# M2354 register map
File version: 1.0
Registers are 32-bit, read-write, reset 0x0 unless marked. A register's access mark holds for its fields unless they carry their own. Offsets are from the block's base; [hi:lo] are bit positions; {n}, {i} and the like mark numbered series.

## SYS (part 1 of 2) — SYS Register Map
Base 0x40000000
0x00 SYS_PDID ro reset 0x235400 — Part Device Identification Number Register
  [31:0] PDID — Part Device Identification Number (Read Only). This register reflects device part number code. Software can read this register to identify which device is used.
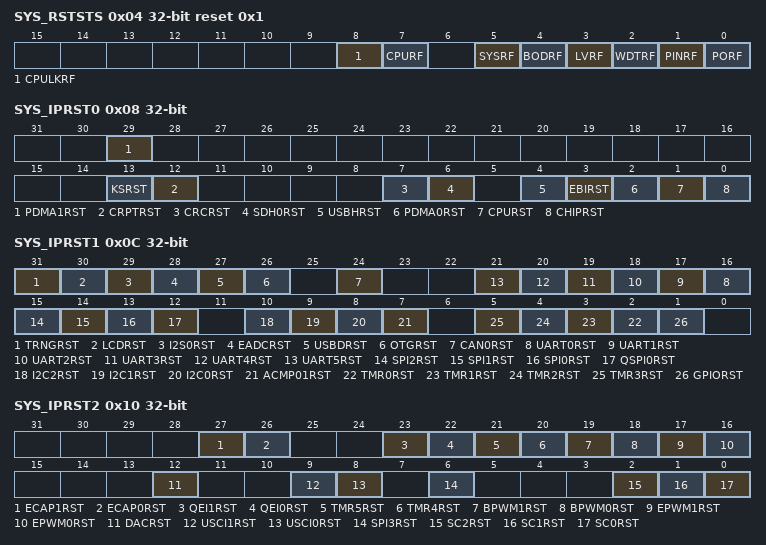
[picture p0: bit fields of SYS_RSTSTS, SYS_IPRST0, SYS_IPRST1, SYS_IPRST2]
0x04 SYS_RSTSTS reset 0x1 — System Reset Status Register
  [8] CPULKRF — CPU Lockup Reset Flag. The CPU Lockup reset flag is set by hardware if Cortex-M23 lockup happened. Note 1: Write 1 to clear this bit to 0. Note 2: When CPU lockup happened under ICE is connected, this flag will set to 1 but chip will not reset.
    0=No reset from CPU lockup happened; 1=The Cortex-M23 lockup happened and chip is reset
  [7] CPURF — CPU Reset Flag. The CPU reset flag is set by hardware if software writes CPURST (SYS_IPRST0[1]) 1 to reset the Cortex-M23 core and Flash Memory Controller (FMC). Note: Write 1 to clear this bit to 0.
    0=No reset from CPU; 1=The Cortex-M23 core and FMC are reset by software setting CPURST to 1
  [5] SYSRF — System Reset Flag. The system reset flag is set by the 'Reset Signal' from the Cortex-M23 core to indicate the previous reset source. Note: Write 1 to clear this bit to 0.
    0=No reset from the Cortex-M23; 1=The Cortex-M23 had issued the reset signal to reset the system by writing 1 to the bit SYSRESETREQ(AIRCR[2], Application Interrupt and Reset Control Register, address = 0xE000ED0C) in system control registers of Cortex-M23 core
  [4] BODRF — BOD Reset Flag. The BOD reset flag is set by the 'Reset Signal' from the Brown-out Detector to indicate the previous reset source. Note: Write 1 to clear this bit to 0.
    0=No reset from BOD; 1=The BOD had issued the reset signal to reset the system
  [3] LVRF — LVR Reset Flag. The LVR reset flag is set by the 'Reset Signal' from the Low Voltage Reset Controller to indicate the previous reset source. Note: Write 1 to clear this bit to 0.
    0=No reset from LVR; 1=The LVR controller had issued the reset signal to reset the system
  [2] WDTRF — WDT Reset Flag. The WDT reset flag is set by the 'Reset Signal' from the Watchdog Timer or Window Watchdog Timer to indicate the previous reset source. Note 1: Write 1 to clear this bit to 0. Note 2: Watchdog Timer register RSTF(WDT_CTL[2]) bit is set if the system has been reset by WDT time-out reset. Window Watchdog Timer register WWDTRF(WWDT_STATUS[1]) bit is set if the system has been reset by WWDT time-out reset. Note 3: Extra Watchdog Timer register RSTF(EWDT_CTL[2]) bit is set if the system has been reset by EWDT time-out reset. Extra Window Watchdog Timer register WWDTRF(EWWDT_STATUS[1]) bit is set if the system has been reset by EWWDT time-out reset.
    0=No reset from watchdog timer or window watchdog timer; 1=The watchdog timer or window watchdog timer had issued the reset signal to reset the system
  [1] PINRF — nRESET Pin Reset Flag. The nRESET pin reset flag is set by the 'Reset Signal' from the nRESET Pin to indicate the previous reset source. Note: Write 1 to clear this bit to 0.
    0=No reset from nRESET pin; 1=Pin nRESET had issued the reset signal to reset the system
  [0] PORF — POR Reset Flag. The POR reset flag is set by the 'Reset Signal' from the Power-on Reset (POR) Controller or bit CHIPRST (SYS_IPRST0[0]) to indicate the previous reset source. Note: Write 1 to clear this bit to 0.
    0=No reset from POR or CHIPRST; 1=Power-on Reset (POR) or CHIPRST had issued the reset signal to reset the system
0x08 SYS_IPRST0 — Peripheral Reset Control Register 0
  [29] PDMA1RST — PDMA1 Controller Reset (Write Protect). Setting this bit to 1 will generate a reset signal to the PDMA1. User needs to set this bit to 0 to release from reset state. Note: This bit is write protected. Refer to the SYS_REGLCTL register.
    0=PDMA1 controller normal operation; 1=PDMA1 controller reset
  [13] KSRST — Key Store Controller Reset (Write Protect). Setting this bit to 1 will generate a reset signal to the Key Store controller. User needs to set this bit to 0 to release from the reset state. Note: This bit is write protected. Refer to the SYS_REGLCTL register.
    0=Key Store controller normal operation; 1=Key Store controller reset
  [12] CRPTRST — CRYPTO Controller Reset (Write Protect). Setting this bit to 1 will generate a reset signal to the CRYPTO controller. User needs to set this bit to 0 to release from the reset state. Note: This bit is write protected. Refer to the SYS_REGLCTL register.
    0=CRYPTO controller normal operation; 1=CRYPTO controller reset
  [7] CRCRST — CRC Calculation Controller Reset (Write Protect). Set this bit to 1 will generate a reset signal to the CRC calculation controller. User needs to set this bit to 0 to release from the reset state. Note: This bit is write protected. Refer to the SYS_REGLCTL register.
    0=CRC calculation controller normal operation; 1=CRC calculation controller reset
  [6] SDH0RST — SDHOST0 Controller Reset (Write Protect). Setting this bit to 1 will generate a reset signal to the SDHOST0 controller. User needs to set this bit to 0 to release from the reset state. Note: This bit is write protected. Refer to the SYS_REGLCTL register.
    0=SDHOST0 controller normal operation; 1=SDHOST0 controller reset
  [4] USBHRST — USB Host Controller Reset (Write Protect). Set this bit to 1 will generate a reset signal to the USB Host. User needs to set this bit to 0 to release from the reset state. Note: This bit is write protected. Refer to the SYS_REGLCTL register.
    0=USB Host controller normal operation; 1=USB Host controller reset
  [3] EBIRST — EBI Controller Reset (Write Protect). Set this bit to 1 will generate a reset signal to the EBI. User needs to set this bit to 0 to release from the reset state. Note: This bit is write protected. Refer to the SYS_REGLCTL register.
    0=EBI controller normal operation; 1=EBI controller reset
  [2] PDMA0RST — PDMA0 Controller Reset (Write Protect). Setting this bit to 1 will generate a reset signal to the PDMA0 (always secure). User needs to set this bit to 0 to release from reset state. Note: This bit is write protected. Refer to the SYS_REGLCTL register.
    0=PDMA0 controller normal operation; 1=PDMA0 controller reset
  [1] CPURST — Processor Core One-shot Reset (Write Protect). Setting this bit will only reset the processor core and Flash Memory Controller(FMC), and this bit will automatically return to 0 after the 2 clock cycles. Note: This bit is write protected. Refer to the SYS_REGLCTL register.
    0=Processor core normal operation; 1=Processor core one-shot reset
  [0] CHIPRST — Chip One-shot Reset (Write Protect). Setting this bit will reset the whole chip, including Processor core and all peripherals, and this bit will automatically return to 0 after the 2 clock cycles. The CHIPRST is same as the POR reset, all the chip controllers is reset and the chip setting from Flash are also reload. About the difference between CHIPRST and SYSRESETREQ(AIRCR[2]), please refer to section 6.2.2. Note: This bit is write protected. Refer to the SYS_REGLCTL register.
    0=Chip normal operation; 1=Chip one-shot reset
0x0C SYS_IPRST1 — Peripheral Reset Control Register 1
  [31] TRNGRST — TRNG Controller Reset
    0=TRNG controller normal operation; 1=TRNG controller reset
  [30] LCDRST — LCD Controller Reset
    0=LCD controller normal operation; 1=LCD controller reset
  [29] I2S0RST — I2S0 Controller Reset
    0=I2S0 controller normal operation; 1=I2S0 controller reset
  [28] EADCRST — EADC Controller Reset
    0=EADC controller normal operation; 1=EADC controller reset
  [27] USBDRST — USBD Controller Reset
    0=USBD controller normal operation; 1=USBD controller reset
  [26] OTGRST — OTG Controller Reset
    0=OTG controller normal operation; 1=OTG controller reset
  [24] CAN0RST — CAN0 Controller Reset
    0=CAN0 controller normal operation; 1=CAN0 controller reset
  [n+16] UART{n}RST (n=0..5) — UART{n} Controller Reset
    0=UART{n} controller normal operation; 1=UART{n} controller reset
  [15] SPI2RST — SPI2 Controller Reset
    0=SPI2 controller normal operation; 1=SPI2 controller reset
  [14] SPI1RST — SPI1 Controller Reset
    0=SPI1 controller normal operation; 1=SPI1 controller reset
  [13] SPI0RST — SPI0 Controller Reset
    0=SPI0 controller normal operation; 1=SPI0 controller reset
  [12] QSPI0RST — QSPI0 Controller Reset
    0=QSPI0 controller normal operation; 1=QSPI0 controller reset
  [10] I2C2RST — I2C2 Controller Reset
    0=I2C2 controller normal operation; 1=I2C2 controller reset
  [9] I2C1RST — I2C1 Controller Reset
    0=I2C1 controller normal operation; 1=I2C1 controller reset
  [8] I2C0RST — I2C0 Controller Reset
    0=I2C0 controller normal operation; 1=I2C0 controller reset
  [7] ACMP01RST — Analog Comparator 0/1 Controller Reset
    0=Analog Comparator 0/1 controller normal operation; 1=Analog Comparator 0/1 controller reset
  [n+2] TMR{n}RST (n=0..3) — Timer{n} Controller Reset
    0=Timer{n} controller normal operation; 1=Timer{n} controller reset
  [1] GPIORST — GPIO Controller Reset
    0=GPIO controller normal operation; 1=GPIO controller reset
0x10 SYS_IPRST2 — Peripheral Reset Control Register 2
  [27] ECAP1RST — ECAP1 Controller Reset
    0=ECAP1 controller normal operation; 1=ECAP1 controller reset
  [26] ECAP0RST — ECAP0 Controller Reset
    0=ECAP0 controller normal operation; 1=ECAP0 controller reset
  [23] QEI1RST — QEI1 Controller Reset
    0=QEI1 controller normal operation; 1=QEI1 controller reset
  [22] QEI0RST — QEI0 Controller Reset
    0=QEI0 controller normal operation; 1=QEI0 controller reset
  [21] TMR5RST — Timer5 Controller Reset
    0=Timer5 controller normal operation; 1=Timer5 controller reset
  [20] TMR4RST — Timer4 Controller Reset
    0=Timer4 controller normal operation; 1=Timer4 controller reset
  [19] BPWM1RST — BPWM1 Controller Reset
    0=BPWM1 controller normal operation; 1=BPWM1 controller reset
  [18] BPWM0RST — BPWM0 Controller Reset
    0=BPWM0 controller normal operation; 1=BPWM0 controller reset
  [17] EPWM1RST — EPWM1 Controller Reset
    0=EPWM1 controller normal operation; 1=EPWM1 controller reset
  [16] EPWM0RST — EPWM0 Controller Reset
    0=EPWM0 controller normal operation; 1=EPWM0 controller reset
  [12] DACRST — DAC Controller Reset
    0=DAC controller normal operation; 1=DAC controller reset
  [9] USCI1RST — USCI1 Controller Reset
    0=USCI1 controller normal operation; 1=USCI1 controller reset
  [8] USCI0RST — USCI0 Controller Reset
    0=USCI0 controller normal operation; 1=USCI0 controller reset
  [6] SPI3RST — SPI3 Controller Reset
    0=SPI3 controller normal operation; 1=SPI3 controller reset
  [2] SC2RST — SC2 Controller Reset
    0=SC2 controller normal operation; 1=SC2 controller reset
  [1] SC1RST — SC1 Controller Reset
    0=SC1 controller normal operation; 1=SC1 controller reset
  [0] SC0RST — SC0 Controller Reset
    0=SC0 controller normal operation; 1=SC0 controller reset
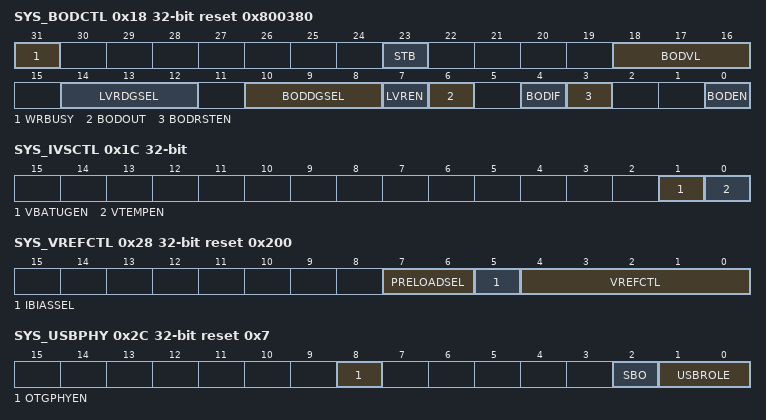
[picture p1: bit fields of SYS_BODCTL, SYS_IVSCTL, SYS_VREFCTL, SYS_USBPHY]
0x18 SYS_BODCTL reset 0x800380 (reset mask 0xFFF0FFF0) — Brown-out Detector Control Register
  [31] WRBUSY ro — Write Busy Flag (Read Only). If SYS_BODCTL is written, this bit is asserted automatically by hardware, and is de-asserted when write procedure is finished.
    0=SYS_BODCTL register is ready for write operation; 1=SYS_BODCTL register is busy on the last write operation. Other write operations are ignored
  [23] STB ro — Circuit Stable Flag (Read Only). This bit indicates LVR and BOD already stable, system cannot detect LVR and BOD event when this bit is not set.
  [18:16] BODVL — Brown-out Detector Threshold Voltage Selection (Write Protect). The default value is set by Flash controller user configuration register CBOV (CONFIG0 [23:21]). Note: These bits are write protected. Refer to the SYS_REGLCTL register.
    0=Brown-out Detector threshold voltage is 1.6V; 1=Brown-out Detector threshold voltage is 1.8V; 2=Brown-out Detector threshold voltage is 2.0V; 3=Brown-out Detector threshold voltage is 2.2V; 4=Brown-out Detector threshold voltage is 2.4V; 5=Brown-out Detector threshold voltage is 2.6V; 6=Brown-out Detector threshold voltage is 2.8V; 7=Brown-out Detector threshold voltage is 3.0V
  [14:12] LVRDGSEL — LVR Output De-glitch Time Select (Write Protect). Note: These bits are write protected. Refer to the SYS_REGLCTL register.
    0=Without de-glitch function; 1=4 system clock (HCLK); 2=8 system clock (HCLK); 3=16 system clock (HCLK); 4=32 system clock (HCLK); 5=64 system clock (HCLK); 6=128 system clock (HCLK); 7=256 system clock (HCLK)
  [10:8] BODDGSEL — Brown-out Detector Output De-glitch Time Select (Write Protect). Note: These bits are write protected. Refer to the SYS_REGLCTL register.
    0=BOD output is sampled by LIRC clock; 1=4 system clock (HCLK); 2=8 system clock (HCLK); 3=16 system clock (HCLK); 4=32 system clock (HCLK); 5=64 system clock (HCLK); 6=128 system clock (HCLK); 7=256 system clock (HCLK)
  [7] LVREN — Low Voltage Reset Enable Bit (Write Protect). The LVR function resets the chip when the input power voltage is lower than LVR circuit setting. LVR function is enabled by default. Note 1: After enabling the bit, the LVR function will be active with 200us delay for LVR output stable (default). Note 2: This bit is write protected. Refer to the SYS_REGLCTL register.
    0=Low Voltage Reset function Disabled; 1=Low Voltage Reset function Enabled
  [6] BODOUT ro — Brown-out Detector Output Status (Read Only). It means the detected voltage is lower than BODVL setting. If the BODEN is 0, BOD function disabled, this bit always responds 0.
    0=Brown-out Detector output status is 0; 1=Brown-out Detector output status is 1
  [4] BODIF — Brown-out Detector Interrupt Flag. Note: Write 1 to clear this bit to 0.
    0=Brown-out Detector does not detect any voltage draft at VDD down through or up through the voltage of BODVL setting; 1=When Brown-out Detector detects the VDD is dropped down through the voltage of BODVL setting or the VDD is raised up through the voltage of BODVL setting, this bit is set to 1 and the brown-out interrupt is requested if brown-out interrupt is enabled
  [3] BODRSTEN — Brown-out Reset Enable Bit (Write Protect). The default value is set by Flash controller user configuration register CBORST(CONFIG0[20]) bit. Note 1: When the Brown-out Detector function is enabled (BODEN high) and BOD reset function is enabled (BODRSTEN high), BOD will assert a signal to reset chip when the detected voltage is lower than the threshold (BODOUT high). When the BOD function is enabled (BODEN high) and BOD interrupt function is enabled (BODRSTEN low), BOD will assert an interrupt if AVDD is lower than BODVL, BOD interrupt will keep till the BODIF set to 0. BOD interrupt can be blocked by disabling the NVIC BOD interrupt or disabling BOD function (setting BODEN low). Note 2: This bit is write protected. Refer to the SYS_REGLCTL register.
    0=Brown-out 'INTERRUPT' function Enabled; 1=Brown-out 'RESET' function Enabled
  [0] BODEN — Brown-out Detector Enable Bit (Write Protect). The default value is set by Flash controller user configuration register CBODEN (CONFIG0 [23]). Note: This bit is write protected. Refer to the SYS_REGLCTL register.
    0=Brown-out Detector function Disabled; 1=Brown-out Detector function Enabled
0x1C SYS_IVSCTL — Internal Voltage Source Control Register
  [1] VBATUGEN — VBAT Unity Gain Buffer Enable Bit. This bit is used to enable/disable VBAT unity gain buffer function. Note: After this bit is set to 1, the value of VBAT unity gain buffer output voltage can be obtained from ADC conversion result.
    0=VBAT unity gain buffer function Disabled (default); 1=VBAT unity gain buffer function Enabled
  [0] VTEMPEN — Temperature Sensor Enable Bit. This bit is used to enable/disable temperature sensor function. Note: After this bit is set to 1, the value of temperature sensor output can be obtained from ADC conversion result. Please refer to ADC chapter for details.
    0=Temperature sensor function Disabled (default); 1=Temperature sensor function Enabled
0x24 SYS_PORCTL0 (reset mask 0xFFFFFF00) — Power-on Reset Controller Register 0
  [15:0] PORMASK — Power-on Reset Mask Enable Bit (Write Protect). When powered on, the POR circuit generates a reset signal to reset the whole chip function, but noise on the power may cause the POR active again. User can mask internal POR signal to avoid unpredictable noise to cause chip reset by writing 0x5AA5 to this field. The POR function will be active again when this field is set to another value or chip is reset by other reset source, including: nRESET, Watchdog, LVR reset, BOD reset, ICE reset command and the software-chip reset function. Note: These bits are write protected. Refer to the SYS_REGLCTL register.
0x28 SYS_VREFCTL reset 0x200 — VREF Control Register
  [7:6] PRELOADSEL — Pre-load Timing Selection (Write Protect). Note: These bits are write protected. Refer to the SYS_REGLCTL register.
    0=pre-load time is 60us for 0.1uF Capacitor; 1=pre-load time is 310us for 1uF Capacitor; 2=pre-load time is 2100us for 4.7uF Capacitor; 3=pre-load time is 2850us for 10uF Capacitor
  [5] IBIASSEL — VREF Bias Current Selection (Write Protect). Note: This bit is write protected. Refer to the SYS_REGLCTL register.
    0=Bias current from MEGBIAS; 1=Bias current from internal
  [4:0] VREFCTL — VREF Control Bits (Write Protect). Note: These bits are write protected. Refer to the SYS_REGLCTL register.
    0=VREF is from external pin; 3=VREF is internal 1.6V; 7=VREF is internal 2.0V; 11=VREF is internal 2.5V; 15=VREF is internal 3.0V
0x2C SYS_USBPHY reset 0x7 — USB PHY Control Register
  [8] OTGPHYEN — USB OTG PHY Enable (Write Protect). This bit is used to enable/disable OTG PHY function.
    0=OTG PHY function Disabled (default); 1=OTG PHY function Enabled
  [2] SBO — Note: This bit must always be kept 1. If set to 0, the result is unpredictable.
  [1:0] USBROLE — USB Role Option (Write Protect). These two bits are used to select the role of USB. Note: These bits are write protected. Refer to the SYS_REGLCTL register.
    0=Standard USB Device mode; 1=Standard USB Host mode; 2=ID dependent mode; 3=On-The-Go device mode (default)
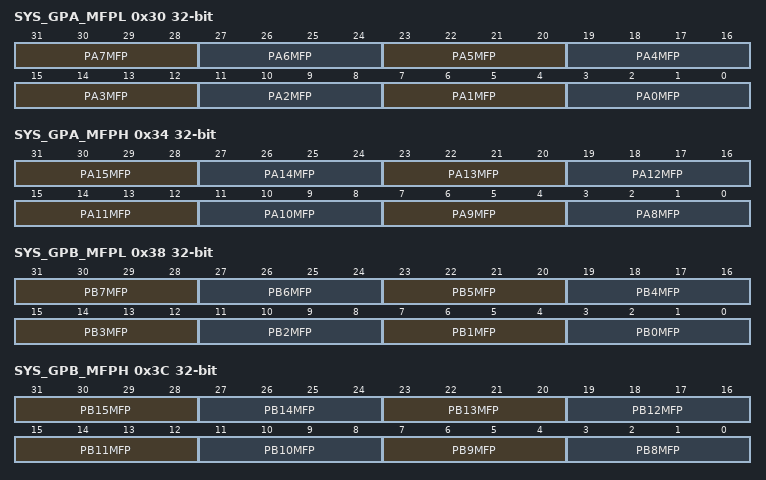
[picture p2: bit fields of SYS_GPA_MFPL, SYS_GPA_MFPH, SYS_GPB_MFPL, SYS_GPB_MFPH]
0x30 SYS_GPA_MFPL — GPIOA Low Byte Multiple Function Control Register
  [31:28] PA7MFP — PA.7 Multi-function Pin Selection
    0=PA.7; 2=EBI_AD7; 4=SPI1_CLK; 6=SC2_DAT; 7=UART0_TXD; 8=I2C1_SCL; 10=TM4; 11=EPWM1_CH4; 12=BPWM1_CH2; 13=ACMP0_WLAT; 14=TM2; 15=INT1
  [27:24] PA6MFP — PA.6 Multi-function Pin Selection
    0=PA.6; 2=EBI_AD6; 4=SPI1_SS; 6=SC2_CLK; 7=UART0_RXD; 8=I2C1_SDA; 10=TM5; 11=EPWM1_CH5; 12=BPWM1_CH3; 13=ACMP1_WLAT; 14=TM3; 15=INT0
  [23:20] PA5MFP — PA.5 Multi-function Pin Selection
    0=PA.5; 3=QSPI0_MISO1; 4=SPI1_I2SMCLK; 6=SC2_nCD; 7=UART0_nCTS; 8=UART5_TXD; 9=I2C0_SCL; 10=CAN0_TXD; 11=UART0_TXD; 12=BPWM0_CH5; 13=EPWM0_CH0; 14=QEI0_INDEX; 15=LCD_SEG29
  [19:16] PA4MFP — PA.4 Multi-function Pin Selection
    0=PA.4; 3=QSPI0_MOSI1; 4=SPI0_I2SMCLK; 6=SC0_nCD; 7=UART0_nRTS; 8=UART5_RXD; 9=I2C0_SDA; 10=CAN0_RXD; 11=UART0_RXD; 12=BPWM0_CH4; 13=EPWM0_CH1; 14=QEI0_A; 15=LCD_SEG28
  [15:12] PA3MFP — PA.3 Multi-function Pin Selection
    0=PA.3; 3=QSPI0_SS; 4=SPI0_SS; 6=SC0_PWR; 7=UART4_TXD; 8=UART1_TXD; 9=I2C1_SCL; 10=I2C0_SMBAL; 11=LCD_SEG27; 12=BPWM0_CH3; 13=EPWM0_CH2; 14=QEI0_B; 15=EPWM1_BRAKE1
  [11:8] PA2MFP — PA.2 Multi-function Pin Selection
    0=PA.2; 3=QSPI0_CLK; 4=SPI0_CLK; 6=SC0_RST; 7=UART4_RXD; 8=UART1_RXD; 9=I2C1_SDA; 10=I2C0_SMBSUS; 11=LCD_SEG26; 12=BPWM0_CH2; 13=EPWM0_CH3
  [7:4] PA1MFP — PA.1 Multi-function Pin Selection
    0=PA.1; 3=QSPI0_MISO0; 4=SPI0_MISO; 6=SC0_DAT; 7=UART0_TXD; 8=UART1_nCTS; 9=I2C2_SCL; 11=LCD_SEG25; 12=BPWM0_CH1; 13=EPWM0_CH4; 15=DAC1_ST
  [3:0] PA0MFP — PA.0 Multi-function Pin Selection
    0=PA.0; 3=QSPI0_MOSI0; 4=SPI0_MOSI; 6=SC0_CLK; 7=UART0_RXD; 8=UART1_nRTS; 9=I2C2_SDA; 11=LCD_SEG24; 12=BPWM0_CH0; 13=EPWM0_CH5; 15=DAC0_ST
0x34 SYS_GPA_MFPH — GPIOA High Byte Multiple Function Control Register
  [31:28] PA15MFP — PA.15 Multi-function Pin Selection
    0=PA.15; 2=I2S0_DO; 3=UART0_RXD; 5=SPI2_MOSI; 6=I2C2_SDA; 7=SC2_CLK; 11=BPWM1_CH5; 12=EPWM0_SYNC_IN; 14=USB_OTG_ID
  [27:24] PA14MFP — PA.14 Multi-function Pin Selection
    0=PA.14; 2=I2S0_DI; 3=UART0_TXD; 5=SPI2_MISO; 6=I2C2_SCL; 7=SC2_DAT; 11=BPWM1_CH4; 12=QEI1_B; 14=USB_D+
  [23:20] PA13MFP — PA.13 Multi-function Pin Selection
    0=PA.13; 2=I2S0_MCLK; 3=UART4_RXD; 4=I2C1_SDA; 5=SPI2_CLK; 6=CAN0_RXD; 7=SC2_RST; 11=BPWM1_CH3; 12=QEI1_A; 14=USB_D-
  [19:16] PA12MFP — PA.12 Multi-function Pin Selection
    0=PA.12; 2=I2S0_BCLK; 3=UART4_TXD; 4=I2C1_SCL; 5=SPI2_SS; 6=CAN0_TXD; 7=SC2_PWR; 11=BPWM1_CH2; 12=QEI1_INDEX; 14=USB_VBUS
  [15:12] PA11MFP — PA.11 Multi-function Pin Selection
    0=PA.11; 1=ACMP0_P0; 2=EBI_nRD; 3=SC2_PWR; 4=SPI2_SS; 6=USCI0_CLK; 7=I2C2_SCL; 9=BPWM0_CH0; 10=EPWM0_SYNC_OUT; 13=TM0_EXT; 14=DAC1_ST
  [11:8] PA10MFP — PA.10 Multi-function Pin Selection
    0=PA.10; 1=ACMP1_P0; 2=EBI_nWR; 3=SC2_RST; 4=SPI2_CLK; 6=USCI0_DAT0; 7=I2C2_SDA; 9=BPWM0_CH1; 10=QEI1_INDEX; 11=ECAP0_IC0; 13=TM1_EXT; 14=DAC0_ST
  [7:4] PA9MFP — PA.9 Multi-function Pin Selection
    0=PA.9; 2=EBI_MCLK; 3=SC2_DAT; 4=SPI2_MISO; 6=USCI0_DAT1; 7=UART1_TXD; 9=BPWM0_CH2; 10=QEI1_A; 11=ECAP0_IC1; 12=TM4_EXT; 13=TM2_EXT
  [3:0] PA8MFP — PA.8 Multi-function Pin Selection
    0=PA.8; 2=EBI_ALE; 3=SC2_CLK; 4=SPI2_MOSI; 6=USCI0_CTL1; 7=UART1_RXD; 9=BPWM0_CH3; 10=QEI1_B; 11=ECAP0_IC2; 12=TM5_EXT; 13=TM3_EXT; 15=INT4
0x38 SYS_GPB_MFPL — GPIOB Low Byte Multiple Function Control Register
  [31:28] PB7MFP — PB.7 Multi-function Pin Selection
    0=PB.7; 1=EADC0_CH7; 2=EBI_nWRL; 4=USCI1_DAT0; 6=UART1_TXD; 8=EBI_nCS0; 10=BPWM1_CH4; 11=EPWM1_BRAKE0; 12=EPWM1_CH4; 13=INT5; 14=USB_VBUS_ST; 15=ACMP0_O
  [27:24] PB6MFP — PB.6 Multi-function Pin Selection
    0=PB.6; 1=EADC0_CH6; 2=EBI_nWRH; 4=USCI1_DAT1; 6=UART1_RXD; 8=EBI_nCS1; 10=BPWM1_CH5; 11=EPWM1_BRAKE1; 12=EPWM1_CH5; 13=INT4; 14=USB_VBUS_EN; 15=ACMP1_O
  [23:20] PB5MFP — PB.5 Multi-function Pin Selection
    0=PB.5; 1=EADC0_CH5. ACMP1_N; 2=EBI_ADR0; 3=SD0_DAT3; 5=SPI1_MISO; 6=I2C0_SCL; 7=UART5_TXD; 8=USCI1_CTL0; 9=SC0_CLK; 10=I2S0_BCLK; 11=EPWM0_CH0; 12=UART2_TXD; 14=TM0; 15=INT0
  [19:16] PB4MFP — PB.4 Multi-function Pin Selection
    0=PB.4; 1=EADC0_CH4. ACMP1_P1; 2=EBI_ADR1; 3=SD0_DAT2; 5=SPI1_MOSI; 6=I2C0_SDA; 7=UART5_RXD; 8=USCI1_CTL1; 9=SC0_DAT; 10=I2S0_MCLK; 11=EPWM0_CH1; 12=UART2_RXD; 14=TM1; 15=INT1
  [15:12] PB3MFP — PB.3 Multi-function Pin Selection
    0=PB.3; 1=EADC0_CH3. ACMP0_N; 2=EBI_ADR2; 3=SD0_DAT1; 5=SPI1_CLK; 6=UART1_TXD; 7=UART5_nRTS; 8=USCI1_DAT1; 9=SC0_RST; 10=I2S0_DI; 11=EPWM0_CH2; 12=I2C1_SCL; 13=TM4; 14=TM2; 15=INT2
  [11:8] PB2MFP — PB.2 Multi-function Pin Selection
    0=PB.2; 1=EADC0_CH2. ACMP0_P1; 2=EBI_ADR3; 3=SD0_DAT0; 5=SPI1_SS; 6=UART1_RXD; 7=UART5_nCTS; 8=USCI1_DAT0; 9=SC0_PWR; 10=I2S0_DO; 11=EPWM0_CH3; 12=I2C1_SDA; 13=TM5; 14=TM3; 15=INT3
  [7:4] PB1MFP — PB.1 Multi-function Pin Selection
    0=PB.1; 1=EADC0_CH1; 2=EBI_ADR8; 3=SD0_CLK; 5=SPI1_I2SMCLK; 6=SPI3_I2SMCLK; 7=UART2_TXD; 8=USCI1_CLK; 9=I2C1_SCL; 10=I2S0_LRCK; 11=EPWM0_CH4; 12=EPWM1_CH4; 13=EPWM0_BRAKE0; 15=QSPI0_MISO1
  [3:0] PB0MFP — PB.0 Multi-function Pin Selection
    0=PB.0; 1=EADC0_CH0; 2=EBI_ADR9; 3=SD0_CMD; 4=SPI2_I2SMCLK; 7=UART2_RXD; 8=SPI0_I2SMCLK; 9=I2C1_SDA; 11=EPWM0_CH5; 12=EPWM1_CH5; 13=EPWM0_BRAKE1; 15=QSPI0_MOSI1
0x3C SYS_GPB_MFPH — GPIOB High Byte Multiple Function Control Register
  [31:28] PB15MFP — PB.15 Multi-function Pin Selection
    0=PB.15; 1=EADC0_CH15; 2=EBI_AD12; 3=SC1_PWR; 4=SPI0_SS; 5=USCI0_CTL1; 6=UART0_nCTS; 7=UART3_TXD; 8=I2C2_SMBAL; 11=EPWM1_CH0; 13=TM0_EXT; 14=USB_VBUS_EN
  [27:24] PB14MFP — PB.14 Multi-function Pin Selection
    0=PB.14; 1=EADC0_CH14; 2=EBI_AD13; 3=SC1_RST; 4=SPI0_CLK; 5=USCI0_DAT1; 6=UART0_nRTS; 7=UART3_RXD; 8=I2C2_SMBSUS; 10=EPWM0_BRAKE1; 11=EPWM1_CH1; 13=TM1_EXT; 14=CLKO; 15=USB_VBUS_ST
  [23:20] PB13MFP — PB.13 Multi-function Pin Selection
    0=PB.13; 1=EADC0_CH13. DAC1_OUT. ACMP0_P3. ACMP1_P3; 2=EBI_AD14; 3=SC1_DAT; 4=SPI0_MISO; 5=USCI0_DAT0; 6=UART0_TXD; 7=UART3_nRTS; 8=I2C2_SCL; 11=EPWM1_CH2; 13=TM2_EXT; 14=TM4_EXT
  [19:16] PB12MFP — PB.12 Multi-function Pin Selection
    0=PB.12; 1=EADC0_CH12. DAC0_OUT. ACMP0_P2. ACMP1_P2; 2=EBI_AD15; 3=SC1_CLK; 4=SPI0_MOSI; 5=USCI0_CLK; 6=UART0_RXD; 7=UART3_nCTS; 8=I2C2_SDA; 9=SD0_nCD; 11=EPWM1_CH3; 13=TM3_EXT; 14=TM5_EXT
  [15:12] PB11MFP — PB.11 Multi-function Pin Selection
    0=PB.11; 1=EADC0_CH11; 2=EBI_ADR16; 5=UART0_nCTS; 6=UART4_TXD; 7=I2C1_SCL; 8=CAN0_TXD; 9=SPI0_I2SMCLK; 10=BPWM1_CH0; 11=SPI3_CLK
  [11:8] PB10MFP — PB.10 Multi-function Pin Selection
    0=PB.10; 1=EADC0_CH10; 2=EBI_ADR17; 4=USCI1_CTL0; 5=UART0_nRTS; 6=UART4_RXD; 7=I2C1_SDA; 8=CAN0_RXD; 10=BPWM1_CH1; 11=SPI3_SS
  [7:4] PB9MFP — PB.9 Multi-function Pin Selection
    0=PB.9; 1=EADC0_CH9; 2=EBI_ADR18; 4=USCI1_CTL1; 5=UART0_TXD; 6=UART1_nCTS; 7=I2C1_SMBAL; 9=I2C0_SCL; 10=BPWM1_CH2; 11=SPI3_MISO; 13=INT7
  [3:0] PB8MFP — PB.8 Multi-function Pin Selection
    0=PB.8; 1=EADC0_CH8; 2=EBI_ADR19; 4=USCI1_CLK; 5=UART0_RXD; 6=UART1_nRTS; 7=I2C1_SMBSUS; 9=I2C0_SDA; 10=BPWM1_CH3; 11=SPI3_MOSI; 13=INT6
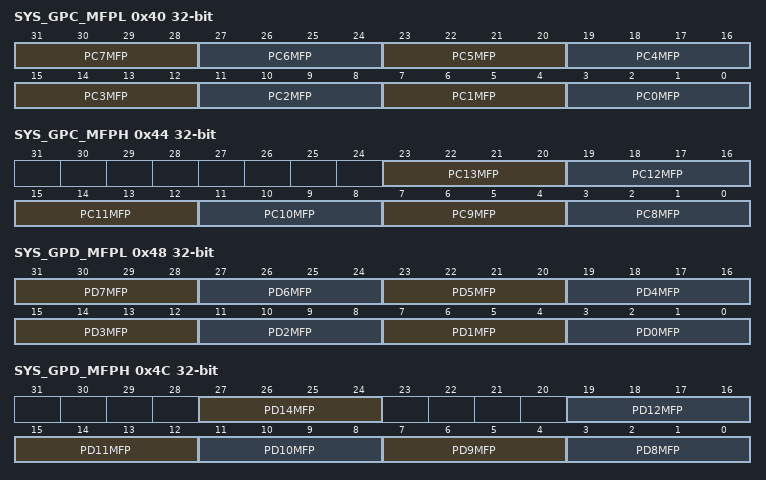
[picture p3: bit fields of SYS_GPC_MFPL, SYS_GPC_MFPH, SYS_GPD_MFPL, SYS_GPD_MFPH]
0x40 SYS_GPC_MFPL — GPIOC Low Byte Multiple Function Control Register
  [31:28] PC7MFP — PC.7 Multi-function Pin Selection
    0=PC.7; 2=EBI_AD9; 4=SPI1_MISO; 5=UART4_TXD; 6=SC2_PWR; 7=UART0_nCTS; 8=I2C1_SMBAL; 11=EPWM1_CH2; 12=BPWM1_CH0; 14=TM0; 15=INT3
  [27:24] PC6MFP — PC.6 Multi-function Pin Selection
    0=PC.6; 2=EBI_AD8; 4=SPI1_MOSI; 5=UART4_RXD; 6=SC2_RST; 7=UART0_nRTS; 8=I2C1_SMBSUS; 11=EPWM1_CH3; 12=BPWM1_CH1; 14=TM1; 15=INT2
  [23:20] PC5MFP — PC.5 Multi-function Pin Selection
    0=PC.5; 2=EBI_AD5; 4=QSPI0_MISO1; 8=UART2_TXD; 9=I2C1_SCL; 10=CAN0_TXD; 11=UART4_TXD; 12=EPWM1_CH0; 15=LCD_COM5/SEG42
  [19:16] PC4MFP — PC.4 Multi-function Pin Selection
    0=PC.4; 2=EBI_AD4; 4=QSPI0_MOSI1; 5=SC1_nCD; 6=I2S0_BCLK; 7=SPI1_I2SMCLK; 8=UART2_RXD; 9=I2C1_SDA; 10=CAN0_RXD; 11=UART4_RXD; 12=EPWM1_CH1; 15=LCD_COM4/SEG43
  [15:12] PC3MFP — PC.3 Multi-function Pin Selection
    0=PC.3; 2=EBI_AD3; 4=QSPI0_SS; 5=SC1_PWR; 6=I2S0_MCLK; 7=SPI1_MISO; 8=UART2_nRTS; 9=I2C0_SMBAL; 11=UART3_TXD; 12=EPWM1_CH2; 15=LCD_COM3
  [11:8] PC2MFP — PC.2 Multi-function Pin Selection
    0=PC.2; 2=EBI_AD2; 4=QSPI0_CLK; 5=SC1_RST; 6=I2S0_DI; 7=SPI1_MOSI; 8=UART2_nCTS; 9=I2C0_SMBSUS; 11=UART3_RXD; 12=EPWM1_CH3; 15=LCD_COM2
  [7:4] PC1MFP — PC.1 Multi-function Pin Selection
    0=PC.1; 2=EBI_AD1; 4=QSPI0_MISO0; 5=SC1_DAT; 6=I2S0_DO; 7=SPI1_CLK; 8=UART2_TXD; 9=I2C0_SCL; 12=EPWM1_CH4; 13=LCD_COM1; 14=ACMP0_O; 15=EADC0_ST
  [3:0] PC0MFP — PC.0 Multi-function Pin Selection
    0=PC.0; 2=EBI_AD0; 4=QSPI0_MOSI0; 5=SC1_CLK; 6=I2S0_LRCK; 7=SPI1_SS; 8=UART2_RXD; 9=I2C0_SDA; 12=EPWM1_CH5; 13=LCD_COM0; 14=ACMP1_O
0x44 SYS_GPC_MFPH — GPIOC High Byte Multiple Function Control Register
  [23:20] PC13MFP — PC.13 Multi-function Pin Selection
    0=PC.13; 2=EBI_ADR10; 3=SC2_nCD; 4=SPI2_I2SMCLK; 6=USCI0_CTL0; 7=UART2_TXD; 9=BPWM0_CH4; 13=CLKO; 14=EADC0_ST
  [19:16] PC12MFP — PC.12 Multi-function Pin Selection
    0=PC.12; 2=EBI_ADR4; 3=UART0_TXD; 4=I2C0_SCL; 6=SPI3_MISO; 9=SC0_nCD; 11=ECAP1_IC2; 12=EPWM1_CH0; 14=ACMP0_O
  [15:12] PC11MFP — PC.11 Multi-function Pin Selection
    0=PC.11; 2=EBI_ADR5; 3=UART0_RXD; 4=I2C0_SDA; 6=SPI3_MOSI; 11=ECAP1_IC1; 12=EPWM1_CH1; 14=ACMP1_O
  [11:8] PC10MFP — PC.10 Multi-function Pin Selection
    0=PC.10; 2=EBI_ADR6; 6=SPI3_CLK; 7=UART3_TXD; 11=ECAP1_IC0; 12=EPWM1_CH2
  [7:4] PC9MFP — PC.9 Multi-function Pin Selection
    0=PC.9; 2=EBI_ADR7; 6=SPI3_SS; 7=UART3_RXD; 12=EPWM1_CH3
  [3:0] PC8MFP — PC.8 Multi-function Pin Selection
    0=PC.8; 2=EBI_ADR16; 4=I2C0_SDA; 5=UART4_nCTS; 8=UART1_RXD; 11=EPWM1_CH1; 12=BPWM1_CH4
0x48 SYS_GPD_MFPL — GPIOD Low Byte Multiple Function Control Register
  [31:28] PD7MFP — PD.7 Multi-function Pin Selection
    0=PD.7; 3=UART1_TXD; 4=I2C0_SCL; 5=SPI1_MISO; 6=USCI1_CLK; 8=SC1_PWR; 15=LCD_SEG14
  [27:24] PD6MFP — PD.6 Multi-function Pin Selection
    0=PD.6; 3=UART1_RXD; 4=I2C0_SDA; 5=SPI1_MOSI; 6=USCI1_DAT1; 8=SC1_RST; 15=LCD_SEG13
  [23:20] PD5MFP — PD.5 Multi-function Pin Selection
    0=PD.5; 4=I2C1_SCL; 5=SPI1_CLK; 6=USCI1_DAT0; 8=SC1_DAT
  [19:16] PD4MFP — PD.4 Multi-function Pin Selection
    0=PD.4; 3=USCI0_CTL0; 4=I2C1_SDA; 5=SPI1_SS; 6=USCI1_CTL1; 8=SC1_CLK; 14=USB_VBUS_ST
  [15:12] PD3MFP — PD.3 Multi-function Pin Selection
    0=PD.3; 2=EBI_AD10; 3=USCI0_CTL1; 4=SPI0_SS; 5=UART3_nRTS; 6=USCI1_CTL0; 7=SC2_PWR; 8=SC1_nCD; 9=UART0_TXD
  [11:8] PD2MFP — PD.2 Multi-function Pin Selection
    0=PD.2; 2=EBI_AD11; 3=USCI0_DAT1; 4=SPI0_CLK; 5=UART3_nCTS; 7=SC2_RST; 9=UART0_RXD
  [7:4] PD1MFP — PD.1 Multi-function Pin Selection
    0=PD.1; 2=EBI_AD12; 3=USCI0_DAT0; 4=SPI0_MISO; 5=UART3_TXD; 6=I2C2_SCL; 7=SC2_DAT
  [3:0] PD0MFP — PD.0 Multi-function Pin Selection
    0=PD.0; 2=EBI_AD13; 3=USCI0_CLK; 4=SPI0_MOSI; 5=UART3_RXD; 6=I2C2_SDA; 7=SC2_CLK; 14=TM2
0x4C SYS_GPD_MFPH — GPIOD High Byte Multiple Function Control Register
  [27:24] PD14MFP — PD.14 Multi-function Pin Selection
    0=PD.14; 2=EBI_nCS0; 3=SPI3_I2SMCLK; 4=SC1_nCD; 5=USCI0_CTL0; 6=SPI0_I2SMCLK; 11=EPWM0_CH4; 15=LCD_SEG0
  [19:16] PD12MFP — PD.12 Multi-function Pin Selection
    0=PD.12; 2=EBI_nCS0; 7=UART2_RXD; 9=BPWM0_CH5; 10=QEI0_INDEX; 13=CLKO; 14=EADC0_ST; 15=INT5
  [15:12] PD11MFP — PD.11 Multi-function Pin Selection
    0=PD.11; 2=EBI_nCS1; 3=UART1_TXD; 4=CAN0_TXD; 10=QEI0_A; 15=INT6
  [11:8] PD10MFP — PD.10 Multi-function Pin Selection
    0=PD.10; 2=EBI_nCS2; 3=UART1_RXD; 4=CAN0_RXD; 10=QEI0_B; 15=INT7
  [7:4] PD9MFP — PD.9 Multi-function Pin Selection
    0=PD.9; 2=EBI_AD7; 3=I2C2_SCL; 4=UART2_nCTS; 15=LCD_COM7/SEG40
  [3:0] PD8MFP — PD.8 Multi-function Pin Selection
    0=PD.8; 2=EBI_AD6; 3=I2C2_SDA; 4=UART2_nRTS; 15=LCD_COM6/SEG41
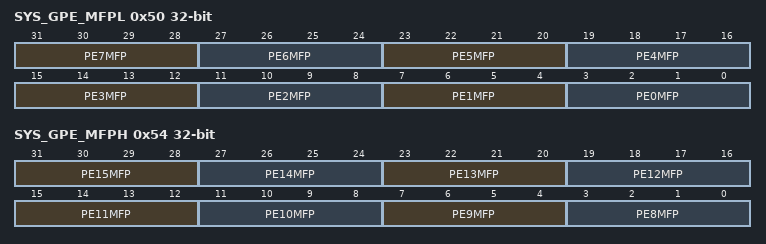
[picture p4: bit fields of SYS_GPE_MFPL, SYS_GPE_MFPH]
0x50 SYS_GPE_MFPL — GPIOE Low Byte Multiple Function Control Register
  [31:28] PE7MFP — PE.7 Multi-function Pin Selection
    0=PE.7; 3=SD0_CMD; 8=UART5_TXD; 11=QEI1_INDEX; 12=EPWM0_CH0; 13=BPWM0_CH5; 15=LCD_SEG12
  [27:24] PE6MFP — PE.6 Multi-function Pin Selection
    0=PE.6; 3=SD0_CLK; 5=SPI3_I2SMCLK; 6=SC0_nCD; 7=USCI0_CTL0; 8=UART5_RXD; 11=QEI1_A; 12=EPWM0_CH1; 13=BPWM0_CH4; 15=LCD_SEG11
  [23:20] PE5MFP — PE.5 Multi-function Pin Selection
    0=PE.5; 2=EBI_nRD; 3=SD0_DAT3; 5=SPI3_SS; 6=SC0_PWR; 7=USCI0_CTL1; 11=QEI1_B; 12=EPWM0_CH2; 13=BPWM0_CH3; 15=LCD_SEG10
  [19:16] PE4MFP — PE.4 Multi-function Pin Selection
    0=PE.4; 2=EBI_nWR; 3=SD0_DAT2; 5=SPI3_CLK; 6=SC0_RST; 7=USCI0_DAT1; 11=QEI0_INDEX; 12=EPWM0_CH3; 13=BPWM0_CH2; 15=LCD_SEG9
  [15:12] PE3MFP — PE.3 Multi-function Pin Selection
    0=PE.3; 2=EBI_MCLK; 3=SD0_DAT1; 5=SPI3_MISO; 6=SC0_DAT; 7=USCI0_DAT0; 11=QEI0_A; 12=EPWM0_CH4; 13=BPWM0_CH1; 15=LCD_SEG8
  [11:8] PE2MFP — PE.2 Multi-function Pin Selection
    0=PE.2; 2=EBI_ALE; 3=SD0_DAT0; 5=SPI3_MOSI; 6=SC0_CLK; 7=USCI0_CLK; 11=QEI0_B; 12=EPWM0_CH5; 13=BPWM0_CH0; 15=LCD_SEG7
  [7:4] PE1MFP — PE.1 Multi-function Pin Selection
    0=PE.1; 2=EBI_AD10; 3=QSPI0_MISO0; 4=SC2_DAT; 5=I2S0_BCLK; 6=SPI1_MISO; 7=UART3_TXD; 8=I2C1_SCL; 9=UART4_nCTS; 15=LCD_SEG6
  [3:0] PE0MFP — PE.0 Multi-function Pin Selection
    0=PE.0; 2=EBI_AD11; 3=QSPI0_MOSI0; 4=SC2_CLK; 5=I2S0_MCLK; 6=SPI1_MOSI; 7=UART3_RXD; 8=I2C1_SDA; 9=UART4_nRTS; 15=LCD_SEG5
0x54 SYS_GPE_MFPH — GPIOE High Byte Multiple Function Control Register
  [31:28] PE15MFP — PE.15 Multi-function Pin Selection
    0=PE.15; 2=EBI_AD9; 3=UART2_RXD; 4=CAN0_RXD; 15=LCD_SEG22
  [27:24] PE14MFP — PE.14 Multi-function Pin Selection
    0=PE.14; 2=EBI_AD8; 3=UART2_TXD; 4=CAN0_TXD; 15=LCD_SEG23
  [23:20] PE13MFP — PE.13 Multi-function Pin Selection
    0=PE.13; 2=EBI_ADR15; 4=I2C0_SCL; 5=UART4_nRTS; 8=UART1_TXD; 10=EPWM0_CH5; 11=EPWM1_CH0; 12=BPWM1_CH5; 13=ECAP1_IC0
  [19:16] PE12MFP — PE.12 Multi-function Pin Selection
    0=PE.12; 2=EBI_ADR14; 4=I2S0_LRCK; 5=SPI2_I2SMCLK; 6=USCI1_CLK; 8=UART1_nRTS; 10=EPWM0_CH4; 13=ECAP1_IC1; 14=TRACE_CLK
  [15:12] PE11MFP — PE.11 Multi-function Pin Selection
    0=PE.11; 2=EBI_ADR13; 4=I2S0_DO; 5=SPI2_SS; 6=USCI1_DAT1; 7=UART3_RXD; 8=UART1_nCTS; 10=EPWM0_CH3; 11=EPWM1_BRAKE1; 13=ECAP1_IC2; 14=TRACE_DATA0
  [11:8] PE10MFP — PE.10 Multi-function Pin Selection
    0=PE.10; 2=EBI_ADR12; 4=I2S0_DI; 5=SPI2_MOSI; 6=USCI1_DAT0; 7=UART3_TXD; 10=EPWM0_CH2; 11=EPWM1_BRAKE0; 12=ECAP0_IC2; 14=TRACE_DATA1; 15=LCD_SEG30
  [7:4] PE9MFP — PE.9 Multi-function Pin Selection
    0=PE.9; 2=EBI_ADR11; 4=I2S0_MCLK; 5=SPI2_MISO; 6=USCI1_CTL0; 7=UART2_RXD; 10=EPWM0_CH1; 11=EPWM0_BRAKE1; 12=ECAP0_IC1; 14=TRACE_DATA2; 15=LCD_SEG31
  [3:0] PE8MFP — PE.8 Multi-function Pin Selection
    0=PE.8; 2=EBI_ADR10; 4=I2S0_BCLK; 5=SPI2_CLK; 6=USCI1_CTL1; 7=UART2_TXD; 10=EPWM0_CH0; 11=EPWM0_BRAKE0; 12=ECAP0_IC0; 14=TRACE_DATA3; 15=LCD_SEG32
